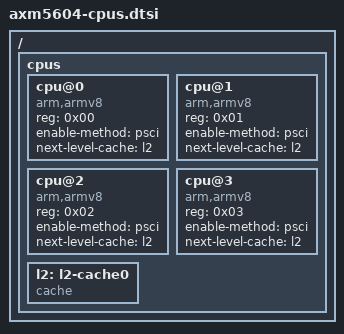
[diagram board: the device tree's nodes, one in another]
// SPDX-License-Identifier: GPL-2.0
// Copyright (C) 2021 INTEL Corporation

/ {
	cpus {
		#address-cells = <1>;
		#size-cells = <0>;

		cpu@0 {
			device_type = "cpu";
			compatible = "arm,armv8";
			reg = <0x00>;
			enable-method = "psci";
			next-level-cache = <&l2>;
		};

		cpu@1 {
			device_type = "cpu";
			compatible = "arm,armv8";
			reg = <0x01>;
			enable-method = "psci";
			next-level-cache = <&l2>;
		};

		cpu@2 {
			device_type = "cpu";
			compatible = "arm,armv8";
			reg = <0x02>;
			enable-method = "psci";
			next-level-cache = <&l2>;
		};

		cpu@3 {
			device_type = "cpu";
			compatible = "arm,armv8";
			reg = <0x03>;
			enable-method = "psci";
			next-level-cache = <&l2>;
		};

		l2: l2-cache0 {
			compatible = "cache";
		};
	};
};
